# ESP32-C3 register map
Vendor: ESPRESSIF SYSTEMS (SHANGHAI) CO., LTD.; Series: ESP32 C-Series; File version: 19
CPU: RV32IMC r0p0, little endian, no MPU, no FPU, 0 interrupt priority bits
Address unit: 32 bits
Registers are 32-bit, read-write, reset 0x0 unless marked. A register's access mark holds for its fields unless they carry their own. Offsets are from the block's base; [hi:lo] are bit positions; {n}, {i} and the like mark numbered series.

## MMU_TABLE — External memory cache MMU table
Base 0x600C5000
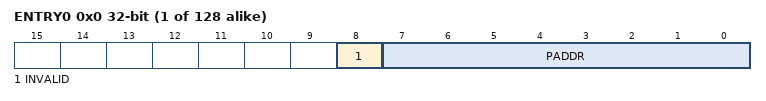
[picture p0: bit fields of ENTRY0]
{0x0+4i} ENTRY{i} (i=0..127) — MMU table entry
  [8] INVALID — Set to mark this entry invalid
  [7:0] PADDR — Physical page number

## GPIO_SD — Sigma-Delta Modulation
Base 0x60004F00
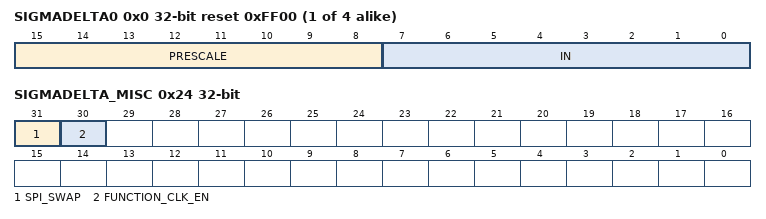
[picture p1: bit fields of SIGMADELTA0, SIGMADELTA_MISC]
{0x0+4i} SIGMADELTA{i} (i=0..3) reset 0xFF00 — Duty Cycle Configure Register of SDM{i}
  [15:8] PRESCALE — This field is used to set a divider value to divide APB clock.
  [7:0] IN — This field is used to configure the duty cycle of sigma delta modulation output.
0x20 CLOCK_GATE — Clock Gating Configure Register
  [31] CLK_EN — Clock enable bit of configuration registers for sigma delta modulation.
0x24 SIGMADELTA_MISC — MISC Register
  [31] SPI_SWAP — Reserved.
  [30] FUNCTION_CLK_EN — Clock enable bit of sigma delta modulation.
0x28 VERSION — Version Control Register

## FE2 — need des
Base 0x60005000
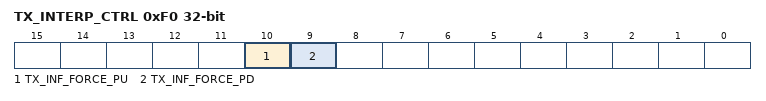
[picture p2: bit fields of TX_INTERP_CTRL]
0xF0 TX_INTERP_CTRL — FE2 TX Interpolation Control Register
  [10] TX_INF_FORCE_PU — Force Power Up field
  [9] TX_INF_FORCE_PD — Force Power Down field

## FE — need des
Base 0x60006000
0x90 GEN_CTRL 2-bit — FE General Control Register
  [5] IQ_EST_FORCE_PU — Force Power Up for IQ Estimation
  [4] IQ_EST_FORCE_PD — Force Power Down for IQ Estimation

## HMAC — HMAC (Hash-based Message Authentication Code) Accelerator
Base 0x6003E000
0x40 SET_START wo — Process control register 0.
  [0] SET_START — Start hmac operation.
0x44 SET_PARA_PURPOSE wo — Configure purpose.
  [3:0] PURPOSE_SET — Set hmac parameter purpose.
0x48 SET_PARA_KEY wo — Configure key.
  [2:0] KEY_SET — Set hmac parameter key.
0x4C SET_PARA_FINISH wo — Finish initial configuration.
  [0] SET_PARA_END — Finish hmac configuration.
0x50 SET_MESSAGE_ONE wo — Process control register 1.
  [0] SET_TEXT_ONE — Call SHA to calculate one message block.
0x54 SET_MESSAGE_ING wo — Process control register 2.
  [0] SET_TEXT_ING — Continue typical hmac.
0x58 SET_MESSAGE_END wo — Process control register 3.
  [0] SET_TEXT_END — Start hardware padding.
0x5C SET_RESULT_FINISH wo — Process control register 4.
  [0] SET_RESULT_END — After read result from upstream, then let hmac back to idle.
0x60 SET_INVALIDATE_JTAG wo — Invalidate register 0.
  [0] SET_INVALIDATE_JTAG — Clear result from hmac downstream JTAG.
0x64 SET_INVALIDATE_DS wo — Invalidate register 1.
  [0] SET_INVALIDATE_DS — Clear result from hmac downstream DS.
0x68 QUERY_ERROR ro — Error register.
  [0] QUERY_CHECK — Hmac configuration state. 0: key are agree with purpose. 1: error
0x6C QUERY_BUSY ro — Busy register.
  [0] BUSY_STATE — Hmac state. 1'b0: idle. 1'b1: busy
{0x80+4i} WR_MESSAGE_MEM[{i}] (i=0..15) access not given — Message block memory.
{0xC0+4i} RD_RESULT_MEM[{i}] (i=0..7) access not given — Result from upstream.
0xF0 SET_MESSAGE_PAD wo — Process control register 5.
  [0] SET_TEXT_PAD — Start software padding.
0xF4 ONE_BLOCK wo — Process control register 6.
  [0] SET_ONE_BLOCK — Don't have to do padding.
0xF8 SOFT_JTAG_CTRL wo — Jtag register 0.
  [0] SOFT_JTAG_CTRL — Turn on JTAG verification.
0xFC WR_JTAG wo — Jtag register 1.
  [31:0] WR_JTAG — 32-bit of key to be compared.

## INTERRUPT_CORE0 — Interrupt Controller (Core 0)
Base 0x600C2000
{0x0+4i} CORE_0_INTR_MAP{i} (i=0..61)
  [4:0] MAP
0xF8 CORE_0_INTR_STATUS{x} (x=REG_0,REG_1; step 0x4) ro — mac intr map register
  [31:0] INTR_STATUS_0 — reg_core0_intr_status_0
0x100 CLOCK_GATE reset 0x1 — mac intr map register
  [0] REG_CLK_EN — reg_core0_reg_clk_en
0x104 CPU_INT_ENABLE — mac intr map register
  [31:0] CPU_INT_ENABLE — reg_core0_cpu_int_enable
0x108 CPU_INT_TYPE — mac intr map register
  [31:0] CPU_INT_TYPE — reg_core0_cpu_int_type
0x10C CPU_INT_CLEAR — mac intr map register
  [31:0] CPU_INT_CLEAR — reg_core0_cpu_int_clear
0x110 CPU_INT_EIP_STATUS ro — mac intr map register
  [31:0] CPU_INT_EIP_STATUS — reg_core0_cpu_int_eip_status
{0x114+4i} CPU_INT_PRI{i} (i=0..31) — mac intr map register
  [3:0] MAP — reg_core0_cpu_pri_0_map
0x194 CPU_INT_THRESH — mac intr map register
  [3:0] CPU_INT_THRESH — reg_core0_cpu_int_thresh
0x7FC INTERRUPT_REG_DATE — mac intr map register
